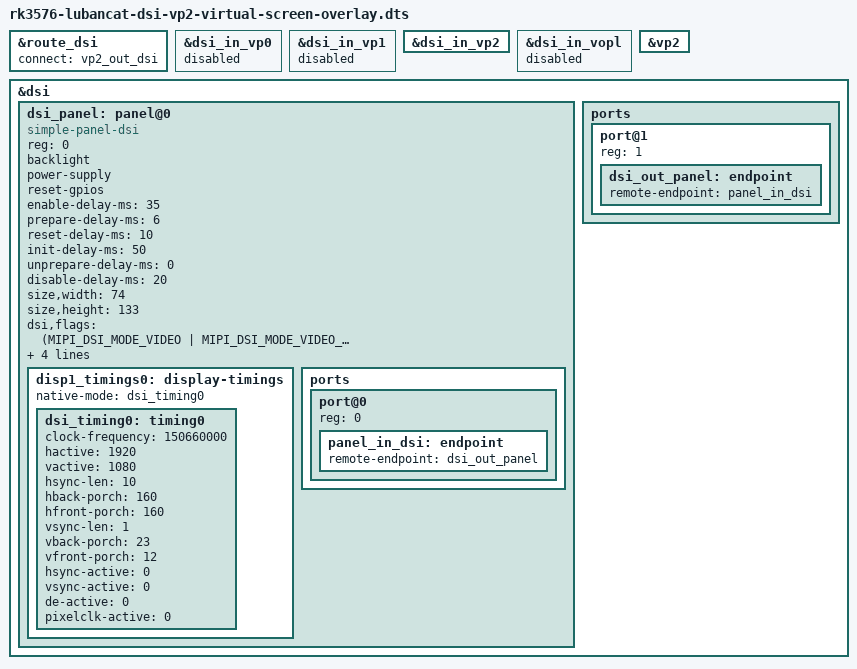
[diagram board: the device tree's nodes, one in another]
/dts-v1/;
/plugin/;

#include <dt-bindings/gpio/gpio.h>
#include <dt-bindings/pinctrl/rockchip.h>
#include <dt-bindings/display/drm_mipi_dsi.h>
#include <dt-bindings/interrupt-controller/irq.h>

/ {
	fragment@0 {
		target = <&route_dsi>;

		__overlay__ {
			status = "okay";
			connect = <&vp2_out_dsi>;
		};
	};

	fragment@1 {
		target = <&dsi_in_vp0>;

		__overlay__ {
			status = "disabled";
		};
	};

	fragment@2 {
		target = <&dsi_in_vp1>;

		__overlay__ {
			status = "disabled";
		};
	};

	fragment@3 {
		target = <&dsi_in_vp2>;

		__overlay__ {
			status = "okay";
		};
	};

	fragment@4 {
		target = <&dsi_in_vopl>;

		__overlay__ {
			status = "disabled";
		};
	};

	fragment@5 {
		target = <&vp2>;

		__overlay__ {
			status = "okay";
		};
	};

	fragment@6 {
		target = <&dsi>;

		__overlay__ {
			status = "okay";
			#address-cells = <1>;
			#size-cells = <0>;

			dsi_panel: panel@0 {
				status = "okay";
				compatible = "simple-panel-dsi";
				reg = <0>;
				backlight;
				power-supply;
				reset-gpios;

				enable-delay-ms = <35>;
				prepare-delay-ms = <6>;
				reset-delay-ms = <10>;
				init-delay-ms = <50>;
				unprepare-delay-ms = <0>;
				disable-delay-ms = <20>;

				size,width = <74>;
				size,height = <133>;

				dsi,flags = <(MIPI_DSI_MODE_VIDEO | MIPI_DSI_MODE_VIDEO_BURST | MIPI_DSI_MODE_LPM | MIPI_DSI_MODE_NO_EOT_PACKET)>;
				dsi,format = <MIPI_DSI_FMT_RGB888>;
				dsi,lanes  = <4>;

				panel-init-sequence = [

				];

				panel-exit-sequence = [

				];

				disp1_timings0: display-timings {
					native-mode = <&dsi_timing0>;
					dsi_timing0: timing0 {
						clock-frequency = <150660000>;
						hactive = <1920>;
						vactive = <1080>;
						hsync-len = <10>;
						hback-porch = <160>;
			   			hfront-porch = <160>;
						vsync-len = <1>;
						vback-porch = <23>;
						vfront-porch = <12>;
						hsync-active = <0>;
						vsync-active = <0>;
						de-active = <0>;
						pixelclk-active = <0>;
					};
				};

				ports {
					#address-cells = <1>;
					#size-cells = <0>;
					port@0 {
						reg = <0>;
						panel_in_dsi: endpoint {
							remote-endpoint = <&dsi_out_panel>;
						};
					};
				};
			};

			ports {
				#address-cells = <1>;
				#size-cells = <0>;

				port@1 {
					reg = <1>;
					dsi_out_panel: endpoint {
						remote-endpoint = <&panel_in_dsi>;
					};
				};
			};
		};
	};
};
